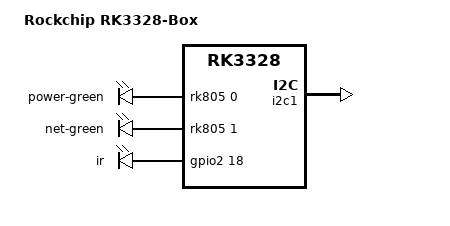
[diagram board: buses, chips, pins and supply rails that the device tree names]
/dts-v1/;

#include <dt-bindings/input/input.h>
#include "rk3328-evb.dtsi"

/ {
	model = "Rockchip RK3328-Box";

	leds {
		compatible = "gpio-leds";
			power-green {
				gpios = <&rk805 0 GPIO_ACTIVE_HIGH>;
				linux,default-trigger = "none";
				default-state = "on";
				mode = <0x23>;
			};

			net-green {
				gpios = <&rk805 1 GPIO_ACTIVE_HIGH>;
				linux,default-trigger = "none";
				default-state = "off";
				mode = <0x05>;
			};

			ir {
				gpios = <&gpio2 18 GPIO_ACTIVE_HIGH>;
				linux,default-trigger = "ir";
				default-state = "off";
				mode = <0x00>;
			};
	};
	
	rk_key: rockchip-key {
		compatible = "rockchip,key";
		status = "okay";

		/*
		io-channels = <&saradc 1>;

		vol-up-key {
			linux,code = <KEY_VOLUMEUP>;
			label = "volume up";
			rockchip,adc_value = <1>;
		};

		vol-down-key {
			linux,code = <KEY_VOLUMEDOWN>;
			label = "volume down";
			rockchip,adc_value = <170>;
		};
		*/

		power-key {
			gpios = <&gpio0 2 GPIO_ACTIVE_LOW>;
			linux,code = <KEY_POWER>;
			label = "power";
			gpio-key,wakeup;
		};
	};

	wireless-wlan {
		wifi_chip_type = "rtl8188eu";
	};
};

&rk805 {
	pwrkey {
		status = "okay";
	};
};

&i2c1 {
	status = "okay";
};

&pwm3 {
	ir_key1 {
		rockchip,usercode = <0xfe01>;
		rockchip,key_table =
			<0xfe KEY_POWER>,       // 0x74
			<0xfd KEY_MUTE>,        // 0x71
			<0xfc KEY_UP>,          // 0x67
			<0xfa KEY_LEFT>,        // 0x69
			<0xf8 KEY_REPLY>,       // 0xe8
			<0xf9 KEY_RIGHT>,       // 0x6a
			<0xf7 KEY_DOWN>,        // 0x6c
			<0xda KEY_BACK>,        // 0x9e
			<0xd9 KEY_TEXT>,        // 0x184
			<0xd8 KEY_HOME>,        // 0x66
			<0xd7 KEY_VOLUMEUP>,    // 0x73
			<0xd6 KEY_VOLUMEDOWN>;  // 0x72
	};

	ir_key2 {
		rockchip,usercode = <0xff00>;
		rockchip,key_table = 
			<0xa8 KEY_POWER>,
			<0xa4 KEY_MUTE>,
			<0xfd KEY_REPLY>,
			<0xf0 KEY_VOLUMEDOWN>,
			<0xb3 KEY_VOLUMEUP>,
			<0xb0 KEY_HOME>,
			<0xe5 KEY_BACK>,
			<0xbc KEY_UP>,
			<0xf5 KEY_DOWN>,
			<0xf9 KEY_LEFT>,
			<0xf1 KEY_RIGHT>,
			<0xb1 KEY_MENU>,        // 0x8b
			<0xb2 KEY_TEXT>,
			<0xef KEY_1>,
			<0xee KEY_2>,
			<0xed KEY_3>,
			<0xec KEY_4>,
			<0xeb KEY_5>,
			<0xea KEY_6>,
			<0xe8 KEY_7>,
			<0xe7 KEY_8>,
			<0xe6 KEY_9>,
			<0xe2 KEY_0>,
			<0xa5 KEY_F1>,          // 0x3b
			<0xad KEY_F2>,
			<0xaf KEY_F3>,
			<0xa7 KEY_F4>,
			<0xe4 KEY_F5>,
			<0xe3 KEY_F6>,
			<0xe1 KEY_F7>,
			<0xe9 KEY_PLAYPAUSE>;   // 0xa4
	};
};
